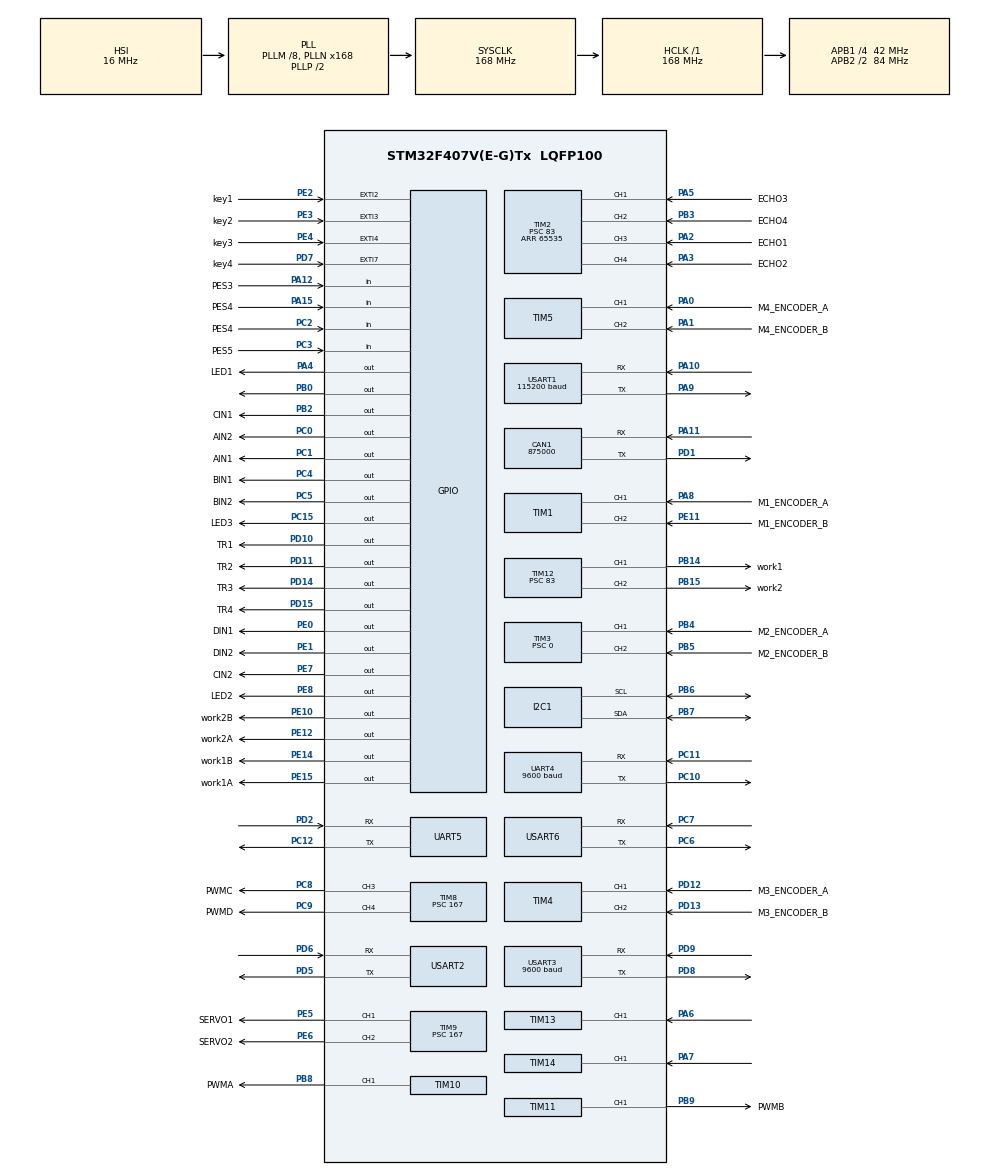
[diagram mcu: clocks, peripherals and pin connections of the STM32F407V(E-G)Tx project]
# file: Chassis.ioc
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CAN1.CalculateBaudRate=875000
CAN1.CalculateTimeBit=1142
CAN1.CalculateTimeQuantum=380.95238095238096
Dma.Request0=USART2_RX
Dma.Request1=USART2_TX
Dma.Request2=USART3_RX
Dma.Request3=USART3_TX
Dma.Request4=UART4_RX
Dma.Request5=UART4_TX
Dma.Request6=UART5_RX
Dma.Request7=UART5_TX
Dma.Request8=USART1_RX
Dma.Request9=USART1_TX
Dma.UART4_RX.4.Direction=DMA_PERIPH_TO_MEMORY
Dma.UART4_RX.4.FIFOMode=DMA_FIFOMODE_DISABLE
Dma.UART4_RX.4.Instance=DMA1_Stream2
Dma.UART4_RX.4.MemDataAlignment=DMA_MDATAALIGN_BYTE
Dma.UART4_RX.4.MemInc=DMA_MINC_ENABLE
Dma.UART4_RX.4.Mode=DMA_NORMAL
Dma.UART4_RX.4.PeriphDataAlignment=DMA_PDATAALIGN_BYTE
Dma.UART4_RX.4.PeriphInc=DMA_PINC_DISABLE
Dma.UART4_RX.4.Priority=DMA_PRIORITY_LOW
Dma.UART4_TX.5.Direction=DMA_MEMORY_TO_PERIPH
Dma.UART4_TX.5.FIFOMode=DMA_FIFOMODE_DISABLE
Dma.UART4_TX.5.Instance=DMA1_Stream4
Dma.UART4_TX.5.MemDataAlignment=DMA_MDATAALIGN_BYTE
Dma.UART4_TX.5.MemInc=DMA_MINC_ENABLE
Dma.UART4_TX.5.Mode=DMA_NORMAL
Dma.UART4_TX.5.PeriphDataAlignment=DMA_PDATAALIGN_BYTE
Dma.UART4_TX.5.PeriphInc=DMA_PINC_DISABLE
Dma.UART4_TX.5.Priority=DMA_PRIORITY_LOW
Dma.UART5_RX.6.Direction=DMA_PERIPH_TO_MEMORY
Dma.UART5_RX.6.FIFOMode=DMA_FIFOMODE_DISABLE
Dma.UART5_RX.6.Instance=DMA1_Stream0
Dma.UART5_RX.6.MemDataAlignment=DMA_MDATAALIGN_BYTE
Dma.UART5_RX.6.MemInc=DMA_MINC_ENABLE
Dma.UART5_RX.6.Mode=DMA_NORMAL
Dma.UART5_RX.6.PeriphDataAlignment=DMA_PDATAALIGN_BYTE
Dma.UART5_RX.6.PeriphInc=DMA_PINC_DISABLE
Dma.UART5_RX.6.Priority=DMA_PRIORITY_LOW
Dma.UART5_TX.7.Direction=DMA_MEMORY_TO_PERIPH
Dma.UART5_TX.7.FIFOMode=DMA_FIFOMODE_DISABLE
Dma.UART5_TX.7.Instance=DMA1_Stream7
Dma.UART5_TX.7.MemDataAlignment=DMA_MDATAALIGN_BYTE
Dma.UART5_TX.7.MemInc=DMA_MINC_ENABLE
Dma.UART5_TX.7.Mode=DMA_NORMAL
Dma.UART5_TX.7.PeriphDataAlignment=DMA_PDATAALIGN_BYTE
Dma.UART5_TX.7.PeriphInc=DMA_PINC_DISABLE
Dma.UART5_TX.7.Priority=DMA_PRIORITY_LOW
Dma.USART1_RX.8.Direction=DMA_PERIPH_TO_MEMORY
Dma.USART1_RX.8.FIFOMode=DMA_FIFOMODE_DISABLE
Dma.USART1_RX.8.Instance=DMA2_Stream2
Dma.USART1_RX.8.MemDataAlignment=DMA_MDATAALIGN_BYTE
Dma.USART1_RX.8.MemInc=DMA_MINC_ENABLE
Dma.USART1_RX.8.Mode=DMA_NORMAL
Dma.USART1_RX.8.PeriphDataAlignment=DMA_PDATAALIGN_BYTE
Dma.USART1_RX.8.PeriphInc=DMA_PINC_DISABLE
Dma.USART1_RX.8.Priority=DMA_PRIORITY_LOW
Dma.USART1_TX.9.Direction=DMA_MEMORY_TO_PERIPH
Dma.USART1_TX.9.FIFOMode=DMA_FIFOMODE_DISABLE
Dma.USART1_TX.9.Instance=DMA2_Stream7
Dma.USART1_TX.9.MemDataAlignment=DMA_MDATAALIGN_BYTE
Dma.USART1_TX.9.MemInc=DMA_MINC_ENABLE
Dma.USART1_TX.9.Mode=DMA_NORMAL
Dma.USART1_TX.9.PeriphDataAlignment=DMA_PDATAALIGN_BYTE
Dma.USART1_TX.9.PeriphInc=DMA_PINC_DISABLE
Dma.USART1_TX.9.Priority=DMA_PRIORITY_LOW
Dma.USART2_RX.0.Direction=DMA_PERIPH_TO_MEMORY
Dma.USART2_RX.0.FIFOMode=DMA_FIFOMODE_DISABLE
Dma.USART2_RX.0.Instance=DMA1_Stream5
Dma.USART2_RX.0.MemDataAlignment=DMA_MDATAALIGN_BYTE
Dma.USART2_RX.0.MemInc=DMA_MINC_ENABLE
Dma.USART2_RX.0.Mode=DMA_NORMAL
Dma.USART2_RX.0.PeriphDataAlignment=DMA_PDATAALIGN_BYTE
Dma.USART2_RX.0.PeriphInc=DMA_PINC_DISABLE
Dma.USART2_RX.0.Priority=DMA_PRIORITY_LOW
Dma.USART2_TX.1.Direction=DMA_MEMORY_TO_PERIPH
Dma.USART2_TX.1.FIFOMode=DMA_FIFOMODE_DISABLE
Dma.USART2_TX.1.Instance=DMA1_Stream6
Dma.USART2_TX.1.MemDataAlignment=DMA_MDATAALIGN_BYTE
Dma.USART2_TX.1.MemInc=DMA_MINC_ENABLE
Dma.USART2_TX.1.Mode=DMA_NORMAL
Dma.USART2_TX.1.PeriphDataAlignment=DMA_PDATAALIGN_BYTE
Dma.USART2_TX.1.PeriphInc=DMA_PINC_DISABLE
Dma.USART2_TX.1.Priority=DMA_PRIORITY_LOW
Dma.USART3_RX.2.Direction=DMA_PERIPH_TO_MEMORY
Dma.USART3_RX.2.FIFOMode=DMA_FIFOMODE_DISABLE
Dma.USART3_RX.2.Instance=DMA1_Stream1
Dma.USART3_RX.2.MemDataAlignment=DMA_MDATAALIGN_BYTE
Dma.USART3_RX.2.MemInc=DMA_MINC_ENABLE
Dma.USART3_RX.2.Mode=DMA_NORMAL
Dma.USART3_RX.2.PeriphDataAlignment=DMA_PDATAALIGN_BYTE
Dma.USART3_RX.2.PeriphInc=DMA_PINC_DISABLE
Dma.USART3_RX.2.Priority=DMA_PRIORITY_LOW
Dma.USART3_TX.3.Direction=DMA_MEMORY_TO_PERIPH
Dma.USART3_TX.3.FIFOMode=DMA_FIFOMODE_DISABLE
Dma.USART3_TX.3.Instance=DMA1_Stream3
Dma.USART3_TX.3.MemDataAlignment=DMA_MDATAALIGN_BYTE
Dma.USART3_TX.3.MemInc=DMA_MINC_ENABLE
Dma.USART3_TX.3.Mode=DMA_NORMAL
Dma.USART3_TX.3.PeriphDataAlignment=DMA_PDATAALIGN_BYTE
Dma.USART3_TX.3.PeriphInc=DMA_PINC_DISABLE
Dma.USART3_TX.3.Priority=DMA_PRIORITY_LOW
Mcu.Family=STM32F4
Mcu.Name=STM32F407V(E-G)Tx
Mcu.Package=LQFP100
NVIC.DMA1_Stream0_IRQn=true\:0\:0\:false\:false\:true\:false\:true\:true
NVIC.DMA1_Stream1_IRQn=true\:0\:0\:false\:false\:true\:false\:true\:true
NVIC.DMA1_Stream2_IRQn=true\:0\:0\:false\:false\:true\:false\:true\:true
NVIC.DMA1_Stream3_IRQn=true\:0\:0\:false\:false\:true\:false\:true\:true
NVIC.DMA1_Stream4_IRQn=true\:0\:0\:false\:false\:true\:false\:true\:true
NVIC.DMA1_Stream5_IRQn=true\:0\:0\:false\:false\:true\:false\:true\:true
NVIC.DMA1_Stream6_IRQn=true\:0\:0\:false\:false\:true\:false\:true\:true
NVIC.DMA1_Stream7_IRQn=true\:0\:0\:false\:false\:true\:false\:true\:true
NVIC.DMA2_Stream2_IRQn=true\:0\:0\:false\:false\:true\:false\:true\:true
NVIC.DMA2_Stream7_IRQn=true\:0\:0\:false\:false\:true\:false\:true\:true
NVIC.EXTI2_IRQn=true\:0\:0\:false\:false\:true\:true\:true\:true
NVIC.EXTI3_IRQn=true\:0\:0\:false\:false\:true\:true\:true\:true
NVIC.EXTI4_IRQn=true\:0\:0\:false\:false\:true\:true\:true\:true
NVIC.EXTI9_5_IRQn=true\:0\:0\:false\:false\:true\:true\:true\:true
NVIC.PriorityGroup=NVIC_PRIORITYGROUP_4
NVIC.TIM1_TRG_COM_TIM11_IRQn=true\:0\:0\:false\:false\:true\:true\:true\:true
NVIC.TIM1_UP_TIM10_IRQn=true\:0\:0\:false\:false\:true\:true\:true\:true
NVIC.TIM2_IRQn=true\:0\:0\:false\:false\:true\:true\:true\:true
NVIC.TIM6_DAC_IRQn=true\:0\:0\:false\:false\:true\:true\:true\:true
NVIC.TIM8_BRK_TIM12_IRQn=true\:0\:0\:false\:false\:true\:true\:true\:true
NVIC.TIM8_TRG_COM_TIM14_IRQn=true\:0\:0\:false\:false\:true\:true\:true\:true
NVIC.TIM8_UP_TIM13_IRQn=true\:0\:0\:false\:false\:true\:true\:true\:true
NVIC.UART4_IRQn=true\:0\:0\:false\:false\:true\:true\:true\:true
NVIC.UART5_IRQn=true\:0\:0\:false\:false\:true\:true\:true\:true
NVIC.USART1_IRQn=true\:0\:0\:false\:false\:true\:true\:true\:true
NVIC.USART2_IRQn=true\:0\:0\:false\:false\:true\:true\:true\:true
NVIC.USART3_IRQn=true\:0\:0\:false\:false\:true\:true\:true\:true
PA0-WKUP.GPIO_Label=M4_ENCODER_A
PA0-WKUP.Signal=S_TIM5_CH1
PA1.GPIO_Label=M4_ENCODER_B
PA1.Signal=S_TIM5_CH2
PA10.Mode=Asynchronous
PA10.Signal=USART1_RX
PA11.Mode=CAN_Activate
PA11.Signal=CAN1_RX
PA12.GPIO_Label=PES3
PA12.Signal=GPIO_Input
PA13.Mode=Serial_Wire
PA13.Signal=SYS_JTMS-SWDIO
PA14.Mode=Serial_Wire
PA14.Signal=SYS_JTCK-SWCLK
PA15.GPIO_Label=PES4
PA15.Signal=GPIO_Input
PA2.GPIO_Label=ECHO1
PA2.GPIO_PuPd=GPIO_NOPULL
PA2.GPIO_Speed=GPIO_SPEED_FREQ_HIGH
PA2.Signal=S_TIM2_CH3
PA3.GPIO_Label=ECHO2
PA3.GPIO_PuPd=GPIO_NOPULL
PA3.GPIO_Speed=GPIO_SPEED_FREQ_HIGH
PA3.Signal=S_TIM2_CH4
PA4.GPIO_Label=LED1
PA4.Signal=GPIO_Output
PA5.GPIO_Label=ECHO3
PA5.GPIO_PuPd=GPIO_NOPULL
PA5.GPIO_Speed=GPIO_SPEED_FREQ_HIGH
PA5.Signal=S_TIM2_CH1_ETR
PA6.Signal=S_TIM13_CH1
PA7.Signal=S_TIM14_CH1
PA8.GPIO_Label=M1_ENCODER_A
PA8.GPIO_PuPd=GPIO_NOPULL
PA8.Signal=S_TIM1_CH1
PA9.Mode=Asynchronous
PA9.Signal=USART1_TX
PB0.GPIO_PuPd=GPIO_NOPULL
PB0.PinState=GPIO_PIN_SET
PB0.Signal=GPIO_Output
PB14.GPIO_Label=work1
PB14.Signal=S_TIM12_CH1
PB15.GPIO_Label=work2
PB15.Signal=S_TIM12_CH2
PB2.GPIO_Label=CIN1
PB2.Signal=GPIO_Output
PB3.GPIO_Label=ECHO4
PB3.GPIO_PuPd=GPIO_NOPULL
PB3.GPIO_Speed=GPIO_SPEED_FREQ_HIGH
PB3.Signal=S_TIM2_CH2
PB4.GPIO_Label=M2_ENCODER_A
PB4.Signal=S_TIM3_CH1
PB5.GPIO_Label=M2_ENCODER_B
PB5.Signal=S_TIM3_CH2
PB6.Mode=I2C
PB6.Signal=I2C1_SCL
PB7.Mode=I2C
PB7.Signal=I2C1_SDA
PB8.GPIO_Label=PWMA
PB8.Signal=S_TIM10_CH1
PB9.GPIO_Label=PWMB
PB9.Signal=S_TIM11_CH1
PC0.GPIO_Label=AIN2
PC0.Signal=GPIO_Output
PC1.GPIO_Label=AIN1
PC1.Signal=GPIO_Output
PC10.Mode=Asynchronous
PC10.Signal=UART4_TX
PC11.Mode=Asynchronous
PC11.Signal=UART4_RX
PC12.Mode=Asynchronous
PC12.Signal=UART5_TX
PC15-OSC32_OUT.GPIO_Label=LED3
PC15-OSC32_OUT.Signal=GPIO_Output
PC2.GPIO_Label=PES4
PC2.Signal=GPIO_Input
PC3.GPIO_Label=PES5
PC3.Signal=GPIO_Input
PC4.GPIO_Label=BIN1
PC4.Signal=GPIO_Output
PC5.GPIO_Label=BIN2
PC5.Signal=GPIO_Output
PC6.Mode=Asynchronous
PC6.Signal=USART6_TX
PC7.Mode=Asynchronous
PC7.Signal=USART6_RX
PC8.GPIO_Label=PWMC
PC8.Signal=S_TIM8_CH3
PC9.GPIO_Label=PWMD
PC9.Signal=S_TIM8_CH4
PD1.Mode=CAN_Activate
PD1.Signal=CAN1_TX
PD10.GPIO_Label=TR1
PD10.PinState=GPIO_PIN_SET
PD10.Signal=GPIO_Output
PD11.GPIO_Label=TR2
PD11.PinState=GPIO_PIN_SET
PD11.Signal=GPIO_Output
PD12.GPIO_Label=M3_ENCODER_A
PD12.Signal=S_TIM4_CH1
PD13.GPIO_Label=M3_ENCODER_B
PD13.Signal=S_TIM4_CH2
PD14.GPIO_Label=TR3
PD14.PinState=GPIO_PIN_SET
PD14.Signal=GPIO_Output
PD15.GPIO_Label=TR4
PD15.PinState=GPIO_PIN_SET
PD15.Signal=GPIO_Output
PD2.Mode=Asynchronous
PD2.Signal=UART5_RX
PD5.Mode=Asynchronous
PD5.Signal=USART2_TX
PD6.Mode=Asynchronous
PD6.Signal=USART2_RX
PD7.GPIO_Label=key4
PD7.GPIO_ModeDefaultEXTI=GPIO_MODE_IT_FALLING
PD7.GPIO_PuPd=GPIO_PULLUP
PD7.Signal=GPXTI7
PD8.Mode=Asynchronous
PD8.Signal=USART3_TX
PD9.Mode=Asynchronous
PD9.Signal=USART3_RX
PE0.GPIO_Label=DIN1
PE0.Signal=GPIO_Output
PE1.GPIO_Label=DIN2
PE1.Signal=GPIO_Output
PE10.GPIO_Label=work2B
PE10.Signal=GPIO_Output
PE11.GPIO_Label=M1_ENCODER_B
PE11.Signal=S_TIM1_CH2
PE12.GPIO_Label=work2A
PE12.Signal=GPIO_Output
PE14.GPIO_Label=work1B
PE14.Signal=GPIO_Output
PE15.GPIO_Label=work1A
PE15.Signal=GPIO_Output
PE2.GPIO_Label=key1
PE2.GPIO_ModeDefaultEXTI=GPIO_MODE_IT_FALLING
PE2.GPIO_PuPd=GPIO_PULLUP
PE2.Signal=GPXTI2
PE3.GPIO_Label=key2
PE3.GPIO_ModeDefaultEXTI=GPIO_MODE_IT_FALLING
PE3.GPIO_PuPd=GPIO_PULLUP
PE3.Signal=GPXTI3
PE4.GPIO_Label=key3
PE4.GPIO_ModeDefaultEXTI=GPIO_MODE_IT_FALLING
PE4.GPIO_PuPd=GPIO_PULLUP
PE4.Signal=GPXTI4
PE5.GPIO_Label=SERVO1
PE5.Signal=S_TIM9_CH1
PE6.GPIO_Label=SERVO2
PE6.Signal=S_TIM9_CH2
PE7.GPIO_Label=CIN2
PE7.Signal=GPIO_Output
PE8.GPIO_Label=LED2
PE8.Signal=GPIO_Output
PH0-OSC_IN.Mode=HSE-External-Oscillator
PH0-OSC_IN.Signal=RCC_OSC_IN
PH1-OSC_OUT.Mode=HSE-External-Oscillator
PH1-OSC_OUT.Signal=RCC_OSC_OUT
ProjectManager.HeapSize=0x200
ProjectManager.StackSize=0x400
ProjectManager.TargetToolchain=MDK-ARM V5.32
RCC.48MHZClocksFreq_Value=84000000
RCC.AHBFreq_Value=168000000
RCC.APB1CLKDivider=RCC_HCLK_DIV4
RCC.APB1Freq_Value=42000000
RCC.APB1TimFreq_Value=84000000
RCC.APB2CLKDivider=RCC_HCLK_DIV2
RCC.APB2Freq_Value=84000000
RCC.APB2TimFreq_Value=168000000
RCC.CortexFreq_Value=168000000
RCC.HCLKFreq_Value=168000000
RCC.HSE_VALUE=8000000
RCC.HSI_VALUE=16000000
RCC.LSE_VALUE=32768
RCC.PLLM=8
RCC.PLLN=168
RCC.RCC_RTC_Clock_Source=RCC_RTCCLKSOURCE_LSI
RCC.RCC_RTC_Clock_SourceVirtual=RCC_RTCCLKSOURCE_LSI
RCC.SYSCLKFreq_VALUE=168000000
RCC.SYSCLKSource=RCC_SYSCLKSOURCE_PLLCLK
RCC.VCOOutputFreq_Value=336000000
SH.S_TIM10_CH1.0=TIM10_CH1,PWM Generation1 CH1
SH.S_TIM11_CH1.0=TIM11_CH1,PWM Generation1 CH1
SH.S_TIM12_CH1.0=TIM12_CH1,PWM Generation1 CH1
SH.S_TIM12_CH2.0=TIM12_CH2,PWM Generation2 CH2
SH.S_TIM13_CH1.0=TIM13_CH1,Input_Capture1_from_TI1
SH.S_TIM14_CH1.0=TIM14_CH1,Input_Capture1_from_TI1
SH.S_TIM1_CH1.0=TIM1_CH1,Encoder_Interface
SH.S_TIM1_CH2.0=TIM1_CH2,Encoder_Interface
SH.S_TIM2_CH1_ETR.0=TIM2_CH1,Input_Capture1_from_TI1
SH.S_TIM2_CH2.0=TIM2_CH2,Input_Capture2_from_TI2
SH.S_TIM2_CH3.0=TIM2_CH3,Input_Capture3_from_TI3
SH.S_TIM2_CH4.0=TIM2_CH4,Input_Capture4_from_TI4
SH.S_TIM3_CH1.0=TIM3_CH1,Encoder_Interface
SH.S_TIM3_CH2.0=TIM3_CH2,Encoder_Interface
SH.S_TIM4_CH1.0=TIM4_CH1,Encoder_Interface
SH.S_TIM4_CH2.0=TIM4_CH2,Encoder_Interface
SH.S_TIM5_CH1.0=TIM5_CH1,Encoder_Interface
SH.S_TIM5_CH2.0=TIM5_CH2,Encoder_Interface
SH.S_TIM8_CH3.0=TIM8_CH3,PWM Generation3 CH3
SH.S_TIM8_CH4.0=TIM8_CH4,PWM Generation4 CH4
SH.S_TIM9_CH1.0=TIM9_CH1,PWM Generation1 CH1
SH.S_TIM9_CH2.0=TIM9_CH2,PWM Generation2 CH2
TIM1.EncoderMode=TIM_ENCODERMODE_TI12
TIM10.Channel=TIM_CHANNEL_1
TIM10.Period=7199
TIM10.Prescaler=167
TIM11.Channel=TIM_CHANNEL_1
TIM11.Period=7199
TIM11.Prescaler=167
TIM12.Channel-PWM\ Generation1\ CH1=TIM_CHANNEL_1
TIM12.Channel-PWM\ Generation2\ CH2=TIM_CHANNEL_2
TIM12.Period=7199
TIM12.Prescaler=83
TIM13.Channel=TIM_CHANNEL_1
TIM14.Channel=TIM_CHANNEL_1
TIM2.AutoReloadPreload=TIM_AUTORELOAD_PRELOAD_ENABLE
TIM2.Channel-Input_Capture1_from_TI1=TIM_CHANNEL_1
TIM2.Channel-Input_Capture2_from_TI2=TIM_CHANNEL_2
TIM2.Channel-Input_Capture3_from_TI3=TIM_CHANNEL_3
TIM2.Channel-Input_Capture4_from_TI4=TIM_CHANNEL_4
TIM2.Period=65535
TIM2.Prescaler=83
TIM3.EncoderMode=TIM_ENCODERMODE_TI12
TIM3.Prescaler=0
TIM4.EncoderMode=TIM_ENCODERMODE_TI12
TIM5.EncoderMode=TIM_ENCODERMODE_TI12
TIM6.AutoReloadPreload=TIM_AUTORELOAD_PRELOAD_ENABLE
TIM6.Period=1000-1
TIM6.Prescaler=839
TIM8.Channel-PWM\ Generation3\ CH3=TIM_CHANNEL_3
TIM8.Channel-PWM\ Generation4\ CH4=TIM_CHANNEL_4
TIM8.Period=7199
TIM8.Prescaler=167
TIM9.Channel-PWM\ Generation1\ CH1=TIM_CHANNEL_1
TIM9.Channel-PWM\ Generation2\ CH2=TIM_CHANNEL_2
TIM9.Prescaler=167
UART4.BaudRate=9600
UART4.VirtualMode=Asynchronous
UART5.VirtualMode=Asynchronous
USART1.BaudRate=115200
USART1.VirtualMode=VM_ASYNC
USART2.VirtualMode=VM_ASYNC
USART3.BaudRate=9600
USART3.VirtualMode=VM_ASYNC
USART6.VirtualMode=VM_ASYNC
VP_TIM10_VS_ClockSourceINT.Mode=Enable_Timer
VP_TIM11_VS_ClockSourceINT.Mode=Enable_Timer
VP_TIM12_VS_ClockSourceINT.Mode=Internal
VP_TIM13_VS_ClockSourceINT.Mode=Enable_Timer
VP_TIM14_VS_ClockSourceINT.Mode=Enable_Timer
VP_TIM2_VS_ClockSourceINT.Mode=Internal
VP_TIM6_VS_ClockSourceINT.Mode=Enable_Timer
VP_TIM8_VS_ClockSourceINT.Mode=Internal
VP_TIM9_VS_ClockSourceINT.Mode=Internal
board=custom

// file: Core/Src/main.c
/* USER CODE BEGIN Header */
/**
  ******************************************************************************
  * @file           : main.c
  * @brief          : Main program body
  ******************************************************************************
  * @attention
  *
  * Copyright (c) 2024 STMicroelectronics.
  * All rights reserved.
  *
  * This software is licensed under terms that can be found in the LICENSE file
  * in the root directory of this software component.
  * If no LICENSE file comes with this software, it is provided AS-IS.
  *
  ******************************************************************************
  */
/* USER CODE END Header */
#include "main.h"
#include "can.h"
#include "dma.h"
#include "i2c.h"
#include "tim.h"
#include "usart.h"
#include "gpio.h"

/* USER CODE BEGIN Includes */
#include "my_uart.h"
#include "motor.h"
#include "SR04.h"
#include "oled.h"
#include "Task_move.h"
#include "pid.h"
#include "key.h"
#include "encoder.h"
#include <stdio.h>
#include "string.h"
/* USER CODE END Includes */

/* USER CODE BEGIN PTD */

/* 测试代码  */

extern float speed_goal;
extern float u_distance;
extern uint8_t corridor_cnt;
extern uint8_t M_speed_state;
uint8_t m1,m2;
/* 测试代码  */

uint8_t display_buf[20];
uint8_t MOVE_STATE;
uint8_t TIME_Task;
float speed=10;
/* USER CODE END PTD */

/* USER CODE BEGIN PM */

//extern float LastDis;////////
/* USER CODE END PM */

void SystemClock_Config(void);

int main(void)
{

  /* MCU Configuration--------------------------------------------------------*/

  /* Reset of all peripherals, Initializes the Flash interface and the Systick. */
  HAL_Init();

  /* Configure the system clock */
  SystemClock_Config();

  /* Initialize all configured peripherals */
  MX_GPIO_Init();
  MX_DMA_Init();
  MX_USART2_UART_Init();
  MX_USART3_UART_Init();
  MX_TIM1_Init();
  MX_TIM3_Init();
  MX_TIM5_Init();
  MX_TIM2_Init();
  MX_TIM4_Init();
  MX_TIM6_Init();
  MX_UART4_Init();
  MX_UART5_Init();
  MX_TIM8_Init();
  MX_TIM9_Init();
  MX_CAN1_Init();
  MX_TIM12_Init();
  MX_USART1_UART_Init();
  MX_TIM10_Init();
  MX_TIM11_Init();
  MX_TIM13_Init();
  MX_TIM14_Init();
  MX_USART6_UART_Init();
  MX_I2C1_Init();
  /* USER CODE BEGIN 2 */
//	OLED_Init();
//  OLED_Clear();
	AUTO_uartDma_init();
	Move_init();
	/* 编码器定时调用 */
	HAL_TIM_Base_Start_IT(&htim6);

	/* 开启定时器(超声波) */
	HAL_TIM_IC_Init (&htim2);
  HAL_TIM_IC_Start_IT(&htim2, TIM_CHANNEL_1);   //开启TIM2的捕获通道1，并开启捕获
	HAL_TIM_IC_Start_IT(&htim2, TIM_CHANNEL_2);
	HAL_TIM_IC_Start_IT(&htim2, TIM_CHANNEL_3);
	HAL_TIM_IC_Start_IT(&htim2, TIM_CHANNEL_4);
  __HAL_TIM_ENABLE_IT(&htim2, TIM_IT_UPDATE);   //使能更新中断
	/* 底盘 */
	HAL_TIM_PWM_Start(&htim10,TIM_CHANNEL_1);
	HAL_TIM_PWM_Start(&htim11,TIM_CHANNEL_1);
	HAL_TIM_PWM_Start(&htim8 ,TIM_CHANNEL_3);
	HAL_TIM_PWM_Start(&htim8 ,TIM_CHANNEL_4);
	/* 作业机构 */
	HAL_TIM_PWM_Start(&htim12 ,TIM_CHANNEL_1);
	HAL_TIM_PWM_Start(&htim12 ,TIM_CHANNEL_2);

	/* 底盘编码器 */
	HAL_TIM_Encoder_Start(&htim1,TIM_CHANNEL_ALL);
	HAL_TIM_Encoder_Start(&htim3,TIM_CHANNEL_ALL);
	HAL_TIM_Encoder_Start(&htim4,TIM_CHANNEL_ALL);
	HAL_TIM_Encoder_Start(&htim5,TIM_CHANNEL_ALL);

  /* USER CODE END 2 */

  /* Infinite loop */
  while (1)
  {

    /* USER CODE BEGIN 3 */
		Working_motor_set(-4000,4000);

		if(MOVE_STATE==1)
		{

			if(TIME_Task==1)
			{
					Move();
//				pid_motor_speed[3].set=speed;
//				pid_motor_speed[3].fdb =E_motor.speedD;
//				PID_Calc(&pid_motor_speed[3]);
//				Motor_current_set(pid_motor_speed[0].out,pid_motor_speed[1].out,pid_motor_speed[2].out,pid_motor_speed[3].out);
					TIME_Task=0;
			}

		}

		printf("%.2f,%.2f\n",u_distance,ultra.F);

  }
  /* USER CODE END 3 */
}

void SystemClock_Config(void)
{
  RCC_OscInitTypeDef RCC_OscInitStruct = {0};
  RCC_ClkInitTypeDef RCC_ClkInitStruct = {0};

  /** Configure the main internal regulator output voltage
  */
  __HAL_RCC_PWR_CLK_ENABLE();
  __HAL_PWR_VOLTAGESCALING_CONFIG(PWR_REGULATOR_VOLTAGE_SCALE1);

  /** Initializes the RCC Oscillators according to the specified parameters
  * in the RCC_OscInitTypeDef structure.
  */
  RCC_OscInitStruct.OscillatorType = RCC_OSCILLATORTYPE_HSI;
  RCC_OscInitStruct.HSIState = RCC_HSI_ON;
  RCC_OscInitStruct.HSICalibrationValue = RCC_HSICALIBRATION_DEFAULT;
  RCC_OscInitStruct.PLL.PLLState = RCC_PLL_ON;
  RCC_OscInitStruct.PLL.PLLSource = RCC_PLLSOURCE_HSI;
  RCC_OscInitStruct.PLL.PLLM = 8;
  RCC_OscInitStruct.PLL.PLLN = 168;
  RCC_OscInitStruct.PLL.PLLP = RCC_PLLP_DIV2;
  RCC_OscInitStruct.PLL.PLLQ = 4;
  if (HAL_RCC_OscConfig(&RCC_OscInitStruct) != HAL_OK)
  {
    Error_Handler();
  }

  /** Initializes the CPU, AHB and APB buses clocks
  */
  RCC_ClkInitStruct.ClockType = RCC_CLOCKTYPE_HCLK|RCC_CLOCKTYPE_SYSCLK
                              |RCC_CLOCKTYPE_PCLK1|RCC_CLOCKTYPE_PCLK2;
  RCC_ClkInitStruct.SYSCLKSource = RCC_SYSCLKSOURCE_PLLCLK;
  RCC_ClkInitStruct.AHBCLKDivider = RCC_SYSCLK_DIV1;
  RCC_ClkInitStruct.APB1CLKDivider = RCC_HCLK_DIV4;
  RCC_ClkInitStruct.APB2CLKDivider = RCC_HCLK_DIV2;

  if (HAL_RCC_ClockConfig(&RCC_ClkInitStruct, FLASH_LATENCY_5) != HAL_OK)
  {
    Error_Handler();
  }
}

void Error_Handler(void)
{
  __disable_irq();
  while (1)
  {
  }
}
